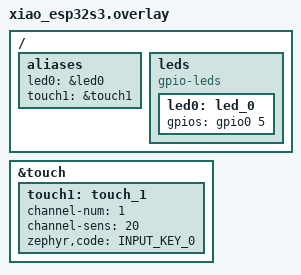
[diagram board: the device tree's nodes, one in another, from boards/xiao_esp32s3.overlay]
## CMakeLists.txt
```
# SPDX-License-Identifier: Apache-2.0

cmake_minimum_required(VERSION 3.20.0)

find_package(Zephyr REQUIRED HINTS $ENV{ZEPHYR_BASE})
project(espTouch)

target_sources(app PRIVATE src/main.c)
```

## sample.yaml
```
sample:
  name: esp32 Touch
tests:
  sample.board.esp32.touch:
    platform_allow: xiao_esp32s3/esp32s3/procpu
    tags:
      - touch
      - input
```

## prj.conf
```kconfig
CONFIG_INPUT=y
CONFIG_INPUT_ESP32_TOUCH_SENSOR=y
```

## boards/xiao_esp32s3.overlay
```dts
#include <zephyr/dt-bindings/input/input-event-codes.h>

// aliases & leds don't exist in the dts file
/ {
aliases {
	led0 = &led0;
	touch1 = &touch1;
};

leds {
	compatible = "gpio-leds";
	led0: led_0 {
		gpios = <&gpio0 5 GPIO_ACTIVE_HIGH>;
	};
};
};

// touch exists in the dts file so need to '&' here
&touch {
	status="okay";
	touch1: touch_1 {
		channel-num = <1>;
		channel-sens = <20>;
		zephyr,code = <INPUT_KEY_0>;	// 11
	};

};
```

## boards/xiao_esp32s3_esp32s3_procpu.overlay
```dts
#include <zephyr/dt-bindings/input/input-event-codes.h>
#include <zephyr/dt-bindings/input/esp32-touch-sensor-input.h>

// aliases & leds don't exist in the dts file
/ {
aliases {
	led1 = &led1;
	touch1 = &touch1;
};

leds {
	compatible = "gpio-leds";
	led1: led_1 {
		gpios = <&gpio0 5 GPIO_ACTIVE_HIGH>;
		label = "TOUCH LED";
	};
};
};

&touch {
	status = "okay";
	touch1: touch_1 {
		channel-num = <1>;
		channel-sens = <20>;
		zephyr,code = <INPUT_KEY_0>;	// 11
	};
};
```

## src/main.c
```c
/*
 * Copyright (c) 2024 Owen O'Hehir
 *
 * SPDX-License-Identifier: Apache-2.0
 */

#include <stdio.h>
#include <zephyr/kernel.h>
#include <zephyr/drivers/gpio.h>
#include <zephyr/input/input.h>
#include <zephyr/dt-bindings/input/input-event-codes.h>

#define SLEEP_TIME_MS   1000

#define LED1_NODE DT_ALIAS(led1)
#if !DT_NODE_HAS_STATUS(LED1_NODE, okay)
#error "Unsupported board: led1 devicetree alias is not defined"
#endif

#define TOUCH1_NODE DT_ALIAS(touch1)
#if !DT_NODE_HAS_STATUS(TOUCH1_NODE, okay)
#error "Unsupported board: touch1 devicetree alias is not defined"
#endif

#ifndef CONFIG_SOC_SERIES_ESP32S3
#error "Unsupported SoC series"
#endif

#ifndef CONFIG_INPUT_ESP32_TOUCH_SENSOR
#error "CONFIG_INPUT_ESP32_TOUCH_SENSOR not set"
#endif

static const struct gpio_dt_spec led = GPIO_DT_SPEC_GET(LED1_NODE, gpios);

static void input_cb(struct input_event *evt) {
    printf("Input event: %d, value: %d, code: %d\n", evt->type, evt->value, evt->code);
    if (evt->code == INPUT_KEY_0) {
        gpio_pin_set_dt(&led, evt->value);
    }
}

INPUT_CALLBACK_DEFINE(NULL, input_cb);

int main(void) {
    k_msleep(SLEEP_TIME_MS);

    printf("Startup of board: %s\n", CONFIG_BOARD);

    if (!gpio_is_ready_dt(&led)) {
        printf("GPIO not ready to for LED at %s pin %d\n", led.port->name, led.pin);
        return 0;
    }

    int ret = gpio_pin_configure_dt(&led, GPIO_OUTPUT_ACTIVE);
    if (ret < 0) {
        printf("Failed to configure LED at %s pin %d\n", led.port->name, led.pin);
        return 0;
    }

    while (1) {
        k_msleep(SLEEP_TIME_MS);
        printf(".");
    }
    return 0;
}
```
